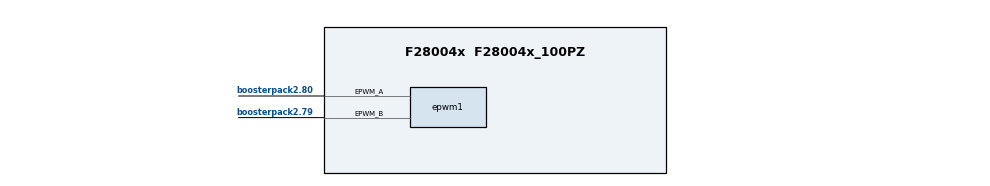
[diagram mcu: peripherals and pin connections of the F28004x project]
/**
 * @cliArgs --board "/boards/LAUNCHXL_F280049C" --device "F28004x" --part "F28004x_100PZ" --package "F28004x_100PZ" --context "system" --product "C2000WARE@5.03.00.00"
 * @versions {"tool":"1.22.0+3893"}
 */

/**
 * Import the modules used in this configuration.
 */
const epwm  = scripting.addModule("/driverlib/epwm.js", {}, false);
const epwm1 = epwm.addInstance();

/**
 * Write custom configuration values to the imported modules.
 */
epwm1.$name                   = "A";
epwm1.epwmTimebase_hsClockDiv = "EPWM_HSCLOCK_DIVIDER_1";
epwm1.epwmTimebase_period     = 2000;
epwm1.epwmCounterCompare_cmpA = 1000;
epwm1.epwm.$assign            = "EPWM1";
epwm1.epwm.epwm_aPin.$assign  = "boosterpack2.80";
epwm1.epwm.epwm_bPin.$assign  = "boosterpack2.79";
scripting.suppress("Connected to hardware,@@@.+?@@@ is connected to EPWM1 BP on the LaunchPad F280049C\\. Consider selecting it in \'use hardware\' above\\. @@@.+?@@@", epwm1.epwm, "epwm_aPin");
scripting.suppress("Connected to hardware,@@@.+?@@@ is connected to EPWM1 BP on the LaunchPad F280049C\\. Consider selecting it in \'use hardware\' above\\. @@@.+?@@@", epwm1.epwm, "epwm_bPin");
